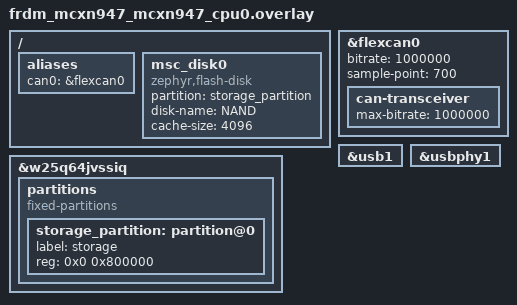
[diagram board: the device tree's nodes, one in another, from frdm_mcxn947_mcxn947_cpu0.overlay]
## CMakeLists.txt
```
# SPDX-License-Identifier: Apache-2.0

cmake_minimum_required(VERSION 3.20.0)

find_package(Zephyr REQUIRED HINTS $ENV{ZEPHYR_BASE})
project(LASER_DAQ)

target_sources(app PRIVATE src/main.c src/Proto/can_proto.c src/Proto/can_sniffer.c src/Proto/can_collect.c)
```

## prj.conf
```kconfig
# ================================================================
# LASER DAQ — Zephyr Kconfig
# ================================================================

# ---- CAN 总线 — 传统 CAN, 1 Mbps ----
CONFIG_CAN=y
# 启用 CAN 子系统
CONFIG_CAN_MCUX_FLEXCAN=y
# NXP MCUX FlexCAN 驱动 (flexcan0/flexcan1)
CONFIG_CAN_LOG_LEVEL_ERR=y
# CAN 驱动日志仅 ERR 级别 (屏蔽空总线 UnHandled status WRN 刷屏)

# ---- 日志 ----
CONFIG_LOG=y
# 启用 Zephyr 日志子系统 (LOG_INF/LOG_ERR 等)

# ---- 存储: Flash + FatFS (W25Q64JV NOR Flash, 8 MB) ----
CONFIG_FLASH=y
# 启用 Flash 驱动子系统
CONFIG_FLASH_MAP=y
# 启用 Flash 分区映射 (overlay 中 partition 需要)
CONFIG_FLASH_PAGE_LAYOUT=y
# 启用页布局查询
CONFIG_FILE_SYSTEM=y
# 启用 VFS 虚拟文件系统层 (统一 fs_open/fs_write 接口)
CONFIG_FAT_FILESYSTEM_ELM=y
# 启用 FatFS (FAT32, PC 兼容)
CONFIG_FS_FATFS_MOUNT_MKFS=y
# 挂载失败时自动格式化
CONFIG_FS_FATFS_LFN=y
# 支持长文件名
CONFIG_FS_FATFS_REENTRANT=y
# FatFS 可重入 (多线程安全, 嗅探定时器 + 主线程并发访问)

# ---- USB 设备栈 (HS USB, Mass Storage) ----
CONFIG_USB_DEVICE_STACK_NEXT=y
# 启用 USB Device Stack Next (新一代 USBD 栈)
CONFIG_USBD_MSC_CLASS=y
# 启用 USB Mass Storage Class 驱动
CONFIG_USBD_MSC_LUNS_PER_INSTANCE=1
# 注册 1 个逻辑单元 (对应 W25Q64JV)
CONFIG_DISK_DRIVER_FLASH=y
# 启用 Flash 磁盘驱动 (将 Flash 分区作为块设备)

# ---- 栈大小 ----
CONFIG_MAIN_STACK_SIZE=4096
# main 线程栈 4KB (FatFS 目录遍历结构较大, 默认 2KB 不够)

# ---- 浮点支持 ----
CONFIG_FPU=y
# 启用硬件 FPU (Cortex-M33 支持单精度)
CONFIG_PICOLIBC_IO_FLOAT=y
# 启用 picolibc 浮点 I/O (%f 格式化)
CONFIG_CBPRINTF_FP_SUPPORT=y
# 启用 cbprintf 浮点格式化支持
CONFIG_REQUIRES_FLOAT_PRINTF=y
# 声明需要浮点打印

# ---- 系统重启 ----
CONFIG_REBOOT=y
# 启用 sys_reboot 系统重启 (EraseFlash 后自动重启)

# ---- 内核堆内存池 ----
CONFIG_HEAP_MEM_POOL_SIZE=4096
# 启用 k_malloc/k_free 动态内存分配 (默认 0=禁用, 这里设为 4KB)
```

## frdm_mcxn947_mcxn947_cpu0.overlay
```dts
/*
 * LASER DAQ — FRDM-MCXN947 设备树覆盖
 *
 * 对端设备: GD32F407 (CAN2, PB5/PB6), 1Mbps, 70% 采样点, 标准帧
 * 本端硬件: FRDM-MCXN947 flexcan0, PIO1_10 (TXD) / PIO1_11 (RXD)
 * 收发器:   TJA1057 (3.3V, 最大 1 Mbps)
 * 存储:     W25Q64JV (8 MB SPI NOR, 挂载在 FlexSPI)
 */

/* ---- 别名: 芯片无关命名, 代码中通过 DT_ALIAS 引用 ---- */

/{
    aliases {
        can0 = &flexcan0;     /* can0 → flexcan0, 代码用 DT_ALIAS(can0) 获取设备 */
    };
};

/* ---- CAN 控制器: flexcan0, 传统 CAN, 1 Mbps, 70% 采样点 ---- */

&flexcan0 {
    status = "okay";          /* 使能 CAN 控制器 (默认 disabled) */
    bitrate = <1000000>;      /* 波特率 1 Mbps */
    sample-point = <700>;     /* 采样点 70.0% (对齐 GD32 端 BS1=13TQ BS2=6TQ) */

    can-transceiver {
        /* TJA1057 — 传统 CAN 收发器, 最大 1 Mbps */
        max-bitrate = <1000000>;
    };
};

/* ---- 外部 Flash: W25Q64JV (8 MB SPI NOR, FlexSPI 接口) ---- */

&w25q64jvssiq {
    status = "okay";          /* 使能 NOR Flash (默认 disabled) */

    partitions {
        compatible = "fixed-partitions";  /* 固定分区表, Zephyr flash_map 识别 */
        #address-cells = <1>;             /* 分区起始地址: 1 个 32-bit 单元 */
        #size-cells = <1>;                /* 分区大小:     1 个 32-bit 单元 */

        storage_partition: partition@0 {  /* 标签 = storage_partition, 代码中引用 */
            label = "storage";            /* 分区名 (调试/识别用) */
            reg = <0x0 0x800000>;         /* 起始 0x0, 大小 0x800000 = 8 MB, 整片用作 FatFS */
        };
    };
};

/* ---- HS USB: USB1 (EHCI, 480 Mbps), 用作 Mass Storage Device ---- */

&usb1 {
    status = "okay";          /* 使能 USB1 控制器 */
};

&usbphy1 {
    status = "okay";          /* 使能 USB1 物理层 (PHY) */
};

/* MSC 磁盘: 将 Flash 分区暴露为 USB 大容量存储设备 */

/ {
    msc_disk0 {
        compatible = "zephyr,flash-disk";    /* Zephyr Flash 磁盘驱动 */
        partition = <&storage_partition>;     /* 绑定到 storage_partition 分区 */
        disk-name = "NAND";                  /* 磁盘名 (Kconfig 中 MASS_STORAGE_DISK_NAME 一致) */
        cache-size = <4096>;                 /* 读写缓存大小 (4 KB) */
    };
};
```

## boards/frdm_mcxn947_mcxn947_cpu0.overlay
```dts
/*
 * LASER DAQ — CAN 设备树覆盖
 *
 * 对端设备: GD32F407 (CAN2, PB5/PB6), 1Mbps, 70% 采样点, 标准帧
 * 本端硬件: FRDM-MCXN947 flexcan0, PIO1_10 (TXD) / PIO1_11 (RXD)
 * 收发器:   TJA1057 (3.3V, 最大 1 Mbps)
 */

&flexcan0 {
	status = "okay";
	bitrate = <1000000>;
	sample-point = <700>;
	sjw = <1>;

	can-transceiver {
		/* TJA1057 — 传统 CAN, 最大 1 Mbps */
		max-bitrate = <1000000>;
	};
};
```

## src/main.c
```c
/*
 * LASER_DAQ - MCXN947 Laser Sensor Data Acquisition
 *
 * 目标: 通过 CAN 总线接入激光传感器，捕获测量数据
 *       在 LCD 屏幕上实时显示采集状态
 *       通过网络（Ethernet/ESP32）将数据上传至服务器
 *       数据用于后续机器学习模型训练
 *
 * FRDM-MCXN947 (Cortex-M33, 150MHz)
 *
 * CAN 协议: 对齐 GD32 GSK5G_MCU 的 can_cmd.h
 *   - MCXN947 node_id = 33 (主控端)
 *   - GD32F407  node_id = 2  (被控端)
 *   - CAN ID = (func_code << 7) | (node_id & 0x7F)
 */

#include <stdint.h>
#include <stdio.h>
#include <zephyr/kernel.h>             /* k_msleep, k_msgq 等内核 API */
#include <zephyr/device.h>             /* device_is_ready, DEVICE_DT_GET */
#include <zephyr/devicetree.h>         /* DT_NODELABEL 等设备树宏 */
#include <zephyr/drivers/can.h>        /* CAN 驱动 API */
#include <zephyr/drivers/uart.h>       /* UART 驱动 API (中断接收) */
#include <zephyr/logging/log.h>        /* 日志模块 */
#include <zephyr/fs/fs.h>			   /* 文件系统 API */

#include <zephyr/storage/flash_map.h>  /* flash_map API, 分区管理 */
#include <ff.h>                        /* FatFS API (f_mount/f_open/f_write 等) */
#include <zephyr/usb/usbd.h>           /* 新一代 USB 设备栈 */
#include <zephyr/usb/class/usbd_msc.h> /* USB Mass Storage Class */
#include <zephyr/usb/bos.h>            /* USB BOS 描述符 */
#include <zephyr/usb/usbd_msg.h>       /* USB 消息类型 (CONFIGURATION 等) */
#include <zephyr/sys/reboot.h>          /* sys_reboot 系统重启 */

#include "Proto/can_proto.h"            /* CAN 协议层 */
#include "Proto/can_sniffer.h"           /* CAN 嗅探模块 */
#include "Proto/can_collect.h"           /* CAN 数据采集模块 */
#include "zephyr/arch/arch_interface.h"
#include "zephyr/sys/printk.h"

LOG_MODULE_REGISTER(laser_daq, LOG_LEVEL_INF); /* 注册日志模块 "laser_daq" */

/* ---- 设备树设备引用 ---- */

/* 通过设备树别名 can0 获取 CAN 设备指针 */
#define CAN_DEV DEVICE_DT_GET(DT_ALIAS(can0))

/* ---- USB Mass Storage 逻辑单元注册 ---- */

USBD_DEFINE_MSC_LUN(nand, "NAND", "Zephyr", "LASER DAQ", "1.00"); /* 注册 MSC LUN */

/* ---- USB 设备上下文 ---- */

USBD_DEVICE_DEFINE(laser_usbd,                        /* 设备上下文名 */
		   DEVICE_DT_GET(DT_NODELABEL(zephyr_udc0)), /* UDC 设备 */
		   0x2FE3, 0x0008);                     /* VID=Zephyr, PID=0008 */

/* USB 字符串描述符 */
USBD_DESC_LANG_DEFINE(laser_lang);                    /* 语言描述符 */
USBD_DESC_MANUFACTURER_DEFINE(laser_mfr, "LASER DAQ");  /* 制造商 */
USBD_DESC_PRODUCT_DEFINE(laser_product, "LASER DAQ");    /* 产品名 */

/* USB 配置描述符 */
USBD_DESC_CONFIG_DEFINE(laser_fs_cfg, "FS MSC");      /* 全速配置描述符 */
USBD_DESC_CONFIG_DEFINE(laser_hs_cfg, "HS MSC");      /* 高速配置描述符 */

/* USB 配置 (全速 + 高速) */
USBD_CONFIGURATION_DEFINE(laser_fs_config, 0, 100, &laser_fs_cfg);  /* 全速 */
USBD_CONFIGURATION_DEFINE(laser_hs_config, 0, 100, &laser_hs_cfg);  /* 高速 */

/* ---- 全局状态 ---- */

static FATFS fat_fs;                     /* FatFS 文件系统对象 (持久化) */
static volatile bool g_storage_locked;    /* USB 连接时置 true, 暂停文件写入 */

/* ---- 串口指令接收 ---- */

#define UART_DEV DEVICE_DT_GET(DT_CHOSEN(zephyr_console)) /* 控制台 UART */
#define UART_CMD_BUF_SIZE 32                               /* 指令缓冲 */

static char s_cmd_buf[UART_CMD_BUF_SIZE];                  /* 行缓冲 */
static int s_cmd_pos;                                      /* 写指针 */

// 网络协议数据结构体
typedef struct {
	uint32_t timestamp;  // 时间戳
	uint16_t node_id;    // 节点 ID
	uint16_t data_length; // 数据长度
	uint8_t data[256];   // 数据内容
} net_data_t;

// 链表结构体定义
typedef struct list {
	struct list *prev;
	net_data_t data;
	struct list *next;
} list_t; 

static list_t head; // 哨兵节点
// 链表内存池定义
K_MEM_SLAB_DEFINE(my_mem_slab, sizeof(list_t), 10, 4);  /* 定义内存池: 10 个节点, 每个节点大小为 sizeof(list_t) */

/* ---- 擦除 Flash 格式化 ---- */

static void erase_flash_and_format(void)
{
	printk("\n=== EraseFlash START ===\n");

	/* 1. 卸载 FatFS */
	FRESULT fres = f_mount(NULL, "NAND:", 0);
	printk("Unmount: %d\n", fres);

	/* 2. 格式化 */
	uint8_t work[FF_MAX_SS];                  /* mkfs 工作缓冲 */
	MKFS_PARM mkfs_opt = {
		.fmt = FM_ANY | FM_SFD,           /* 自动选择 FAT 类型 */
		.n_fat = 1,                       /* 单 FAT 表 */
		.align = 0,                       /* 自动获取扇区大小 */
		.n_root = 512,                    /* 根目录条目数 */
		.au_size = 0                      /* 自动计算簇大小 */
	};
	fres = f_mkfs("NAND:", &mkfs_opt, work, sizeof(work));
	printk("Format: %d (%s)\n", fres, (fres == FR_OK) ? "OK" : "FAIL");

	/* 3. 重启系统 — 格式化后让启动流程自动挂载并重建目录 */
	printk("Rebooting in 1s...\n\n");
	k_msleep(1000);                               /* 等待日志输出完成 */
	sys_reboot(SYS_REBOOT_COLD);                  /* 冷重启 */
}

/* ---- UART RX 中断回调 ---- */

static void uart_rx_cb(const struct device *dev, void *user_data)
{
	(void)user_data;
	uint8_t c;

	/* 从 FIFO 取出所有已接收的字节 */
	while (uart_fifo_read(dev, &c, 1) == 1) {
		if (c == '\r' || c == '\n') {
			/* 换行 → 指令完成 */
			if (s_cmd_pos > 0) {
				s_cmd_buf[s_cmd_pos] = '\0';
				printk("\n[CMD] %s\n", s_cmd_buf);

				/* 匹配指令 */
				if (strcmp(s_cmd_buf, "EraseFlash") == 0) {
					erase_flash_and_format();
				} else if (strcmp(s_cmd_buf, "CollectStart") == 0) {
					can_collect_start();          /* 启动采集 */
				} else if (strcmp(s_cmd_buf, "CollectStop") == 0) {
					can_collect_stop();           /* 停止采集 */
				} else if (strcmp(s_cmd_buf, "Collect?") == 0) {
					printk("Collect: %s (seq=%u)\n",
					       can_collect_is_active() ? "ACTIVE" : "STOPPED",
					       can_collect_get_period()); /* 查状态 */
				} else if (strncmp(s_cmd_buf, "Period=", 7) == 0) {
					uint32_t period;
					if (sscanf(s_cmd_buf + 7, "%u", &period) == 1) {
						can_collect_set_period(period); /* 写入配置, 需重启生效 */
					} else {
						printk("Usage: Period=500\n");
					}
				} else if (strcmp(s_cmd_buf, "Period?") == 0) {
					printk("Period: %u ms (default 500)\n",
					       can_collect_get_period());
				} else if (strcmp(s_cmd_buf, "Help?") == 0) {
					printk(
						"\n=== LASER DAQ Commands ===\n"
						"CollectStart  - Start data collection\n"
						"CollectStop   - Stop data collection\n"
						"Collect?      - Query collection status\n"
						"Period=N      - Set report period (50-60000ms, reboot)\n"
						"Period?       - Query report period\n"
						"EraseFlash    - Format NOR flash\n"
						"Help?         - Show this help\n"
					);
				} else {
					printk("Unknown: %s\n", s_cmd_buf);
				}
				s_cmd_pos = 0;
			}
		} else if (c == '\b' || c == 0x7F) {
			/* 退格 */
			if (s_cmd_pos > 0) s_cmd_pos--;
		} else if (c >= ' ' && c <= '~') {
			/* 可打印字符 */
			if (s_cmd_pos < UART_CMD_BUF_SIZE - 1) {
				s_cmd_buf[s_cmd_pos++] = c;
				printk("%c", c);          /* 回显 */
			}
		}
	}
}

/* ---- USB 消息回调: 检测主机连接/断开 ---- */

static void usb_status_cb(struct usbd_context *const ctx,
			  const struct usbd_msg *const msg)
{
	if (msg->type == USBD_MSG_CONFIGURATION) {
		/* status != 0 → 主机已配置设备, 文件系统被 PC 独占 */
		g_storage_locked = (msg->status != 0);
		if (g_storage_locked) {
			LOG_WRN("USB configured, storage writes suspended");
		} else {
			LOG_INF("USB deconfigured, storage writes resumed");
		}
	} else if (msg->type == USBD_MSG_VBUS_REMOVED) {
		/* VBUS 移除 → 物理断开, 恢复文件写入 */
		g_storage_locked = false;
		LOG_INF("USB disconnected, storage writes resumed");
	}
}

/* ---- 子系统初始化 ---- */

static int init_can_collector(void);    /* CAN 数据采集子系统 */
static int init_storage(void);          /* FatFS 存储子系统 */
static int init_usb_msc(void);          /* USB MSC 初始化 */
static int init_lcd_display(void);      /* LCD 显示子系统 */
static int init_network_upload(void);   /* 网络上传子系统 */
static int init_uart_cmd(void);         /* 串口指令接收 */

/* ---- 线程入口 ---- */

void can_rx_thread(void *, void *, void *);  /* CAN 接收处理线程 */

/* 线程栈定义 */
K_THREAD_DEFINE(can_rx_tid, 2048,       /* 线程 ID + 栈大小 2048 字节 */
		can_rx_thread, NULL, NULL, NULL, /* 入口函数 + 参数（无） */
		7, 0, 0);                       /* 优先级 7, 无延迟启动 */

/* ================================================================
 * USB Mass Storage 初始化
 * ================================================================ */

static int init_usb_msc(void)
{
	int err;                                      /* 返回值 */

	/* 注册 USB 字符串描述符 */
	err = usbd_add_descriptor(&laser_usbd, &laser_lang); /* 语言 */
	if (err) { return err; }
	err = usbd_add_descriptor(&laser_usbd, &laser_mfr);  /* 制造商 */
	if (err) { return err; }
	err = usbd_add_descriptor(&laser_usbd, &laser_product); /* 产品名 */
	if (err) { return err; }

	/* 注册全速配置 + 高速配置 + 自动注册 MSC 类 */
	err = usbd_add_configuration(&laser_usbd, USBD_SPEED_FS, &laser_fs_config);
	if (err) { return err; }
	err = usbd_register_all_classes(&laser_usbd, USBD_SPEED_FS, 1, NULL);
	if (err) { return err; }

	if (usbd_caps_speed(&laser_usbd) == USBD_SPEED_HS) {
		err = usbd_add_configuration(&laser_usbd, USBD_SPEED_HS,
					     &laser_hs_config); /* 高速配置 */
		if (err) { return err; }
		err = usbd_register_all_classes(&laser_usbd, USBD_SPEED_HS,
						1, NULL);   /* 注册 MSC 类 */
		if (err) { return err; }
	}

	/* 初始化并启用 USB 设备 */
	err = usbd_init(&laser_usbd);                 /* 初始化 USBD 栈 */
	if (err) { return err; }
	usbd_msg_register_cb(&laser_usbd, usb_status_cb); /* 注册 USB 状态回调 */
	err = usbd_enable(&laser_usbd);               /* 启用 USB, 开始枚举 */
	if (err) { return err; }

	return 0;                                     /* 成功 */
}

/* ================================================================
 * main — 系统入口
 * ================================================================ */

int main(void)
{
	printk("\n========================================\n");  /* 启动横幅 */
	printk("  MCXN947 Laser Data Collector\n");
	printk("========================================\n\n");

	LOG_INF("System boot complete, initializing subsystems...");  /* 日志: 启动完成 */

	/* 1. CAN 数据采集子系统 — flexcan0 @ 1Mbps, 70% 采样点 */
	if (init_can_collector() < 0) {
		LOG_ERR("CAN collector init failed");   /* 初始化失败日志 */
	}

	/* 2. FatFS 存储子系统 — W25Q64JV NOR Flash 8 MB */
	if (init_storage() < 0) {
		LOG_ERR("Storage init failed");         /* 存储初始化失败 */
	}

	/* 3. 串口指令 — 接收 EraseFlash 等控制台指令 */
	if (init_uart_cmd() < 0) {
		LOG_ERR("UART CMD init failed");        /* 串口初始化失败 */
	}

	/* 4. USB Mass Storage — HS USB, 暴露 /NAND: 为 U 盘 */
	if (init_usb_msc() < 0) {
		LOG_ERR("USB MSC init failed");         /* USB 初始化失败 */
	}

	/* 5. LCD 显示子系统 */
	if (init_lcd_display() < 0) {
		LOG_ERR("LCD display init failed");
	}

	/* 6. CAN 嗅探 — 全量捕获总线帧, 按 node_id 存入 CSV */
	if (can_sniffer_init() < 0) {
		LOG_ERR("CAN sniffer init failed");       /* 嗅探初始化失败 */
	}

	/* 7. CAN 采集 — 主动轮询各 K64 测量值, 窄表 CSV */
	if (can_collect_init(CAN_DEV) < 0) {
		LOG_ERR("CAN collect init failed");       /* 采集初始化失败 */
	}

	/* 8. 网络上传子系统 */
	if (init_network_upload() < 0) {
		LOG_ERR("Network upload init failed");
	}

	LOG_INF("All subsystems initialized, entering main loop");  /* 就绪 */

	while (1) {
		/* 主循环: 轮询各 K64 采集数据 + 批量刷盘 */
		can_collect_poll(CAN_DEV);                /* 发送查询指令 */
		if (!g_storage_locked) {
			can_sniffer_flush();                  /* 嗅探数据写 CSV */
			can_collect_flush();                  /* 采集数据写 CSV */
		}
		k_msleep(COLLECT_POLL_PERIOD_MS);         /* 轮询间隔 */
	}

	return 0;
}

/* ================================================================
 * CAN 数据采集子系统
 * ================================================================ */

static int init_can_collector(void)
{
	LOG_INF("CAN collector: initializing flexcan0...");  /* 开始初始化 */

	/* 步骤1: 检查设备是否就绪（设备树已配置 + 驱动已加载） */
	if (!device_is_ready(CAN_DEV)) {
		LOG_ERR("CAN device not ready");      /* 设备不可用 */
		return -1;
	}
	LOG_INF("CAN device found: %s", CAN_DEV->name);  /* 打印设备名 */

	/* 步骤2: 设置为环回模式, 进行自检 */
	int ret = can_set_mode(CAN_DEV, CAN_MODE_LOOPBACK); /* 环回模式 */
	if (ret != 0) {
		LOG_ERR("CAN set loopback mode failed: %d", ret); /* 模式设置失败 */
		return -1;
	}

	/* 步骤3: 初始化协议层 (配置 RX 滤波器, 设置 node_id=33) */
	ret = can_proto_init(CAN_DEV);
	if (ret < 0) {
		LOG_ERR("CAN proto init failed: %d", ret); /* 协议初始化失败 */
		return -1;
	}

	/* 步骤4: 启动 CAN 控制器 */
	ret = can_start(CAN_DEV);
	if (ret != 0) {
		LOG_ERR("CAN start failed: %d", ret);  /* 启动失败 */
		return -1;
	}

	/* 步骤5: 环回自检 — TX→RX 内部回环, 验证通信通路 */
	can_proto_loopback_test(CAN_DEV);                /* 发送 3 帧测试数据 */

	/* 步骤6: 切换到正常模式 */
	can_stop(CAN_DEV);                               /* 先停止 */
	ret = can_set_mode(CAN_DEV, CAN_MODE_NORMAL);    /* 正常模式 */
	if (ret != 0) {
		LOG_ERR("CAN set normal mode failed: %d", ret); /* 切换失败 */
		return -1;
	}
	ret = can_start(CAN_DEV);                        /* 重新启动 */
	if (ret != 0) {
		LOG_ERR("CAN restart failed: %d", ret);    /* 重启失败 */
		return -1;
	}

	LOG_INF("CAN collector: flexcan0 started, 1Mbps, node_id=%d, waiting for frames",
		g_can_node_id);                           /* 打印节点 ID */
	return 0;  /* 成功 */
}

/* ================================================================
 * CAN 接收线程 — 协议派发
 * ================================================================ */

void can_rx_thread(void *arg1, void *arg2, void *arg3)
{
	(void)arg1; (void)arg2; (void)arg3;        /* 未使用参数 */

	struct can_frame frame;                      /* CAN 帧缓冲区 */
	int drained;                                 /* 本次排空帧数 */

	while (1) {
		drained = 0;
		/* 批量排空消息队列: 避免单帧处理期间新帧堆积溢出 */
		while (k_msgq_get(&can_rx_msgq, &frame, K_NO_WAIT) == 0) {
			can_sniffer_feed(&frame);             /* 原始嗅探 */
			can_collect_feed(&frame);             /* 采集解析 */
			drained++;
		}
		/* 队列空则阻塞等待下一帧 */
		if (drained == 0) {
			k_msgq_get(&can_rx_msgq, &frame, K_FOREVER);
			can_sniffer_feed(&frame);             /* 原始嗅探 */
			can_collect_feed(&frame);             /* 采集解析 */
		}
	}
}

/* ================================================================
 * FatFS + USB MSC 存储子系统 — W25Q64JV NOR Flash 8 MB
 * ================================================================ */

/* 递归遍历目录, 打印文件/子目录 */
static void print_dir(const char *path, int depth)
{
	struct fs_dir_t dir;
	fs_dir_t_init(&dir);                          /* 初始化目录对象 */
	int ret = fs_opendir(&dir, path);             /* 打开目录 */
	if (ret < 0) {
		LOG_WRN("Cannot open %s: %d", path, ret); /* 打开失败 */
		return;
	}

	while (1) {
		struct fs_dirent entry = { 0 };           /* 目录项 */
		ret = fs_readdir(&dir, &entry);           /* 读取一条 */
		if (ret < 0 || entry.name[0] == '\0') {
			break;                                /* 读完或出错 */
		}

		/* 跳过 . 和 .. */
		if (entry.name[0] == '.' && (entry.name[1] == '\0' ||
		    (entry.name[1] == '.' && entry.name[2] == '\0'))) {
			continue;
		}

		/* 缩进打印 */
		for (int i = 0; i < depth; i++) {
			printk("  ");                         /* 每层缩进2空格 */
		}
		printk("%c %8zu %s\n",
		       (entry.type == FS_DIR_ENTRY_DIR) ? 'D' : 'F', /* 类型 */
		       entry.size,                         /* 大小 */
		       entry.name);                        /* 名称 */

		/* 递归进入子目录 */
		if (entry.type == FS_DIR_ENTRY_DIR) {
			char sub_path[280];                   /* 子目录路径 */
			snprintf(sub_path, sizeof(sub_path), "%s/%s", path, entry.name);
			print_dir(sub_path, depth + 1);       /* 递归遍历 */
		}
	}
	fs_closedir(&dir);                            /* 关闭目录 */
}

static int init_storage(void)
{
	LOG_INF("Storage: mounting FatFS on W25Q64JV..."); /* 开始挂载 */

	int ret;                                      /* 返回值 */

	/* 配置挂载参数 */
	struct fs_mount_t mp = {
		.type = FS_FATFS,                         /* 文件系统类型: FatFS */
		.fs_data = &fat_fs,                       /* FatFS 对象 */
		.storage_dev = (void *)PARTITION_ID(storage_partition), /* Flash 分区 */
		.mnt_point = "/NAND:",                    /* 挂载点 */
	};

	ret = fs_mount(&mp);                          /* 执行挂载 */
	if (ret < 0) {
		LOG_ERR("FatFS mount failed: %d", ret);   /* 挂载失败 */
		return -1;
	}
	LOG_INF("FatFS mounted at /NAND:");           /* 挂载成功 */

	/* 打印文件系统信息 */
	struct fs_statvfs stat;
	ret = fs_statvfs("/NAND:", &stat);            /* 查询文件系统状态 */
	if (ret == 0) {
		LOG_INF("FS: block=%luB total=%lu free=%lu",
			stat.f_bsize,                         /* 块大小 */
			stat.f_blocks,                        /* 总块数 */
			stat.f_bfree);                        /* 空闲块数 */
	}

	/* 递归遍历并打印文件系统内容 */
	LOG_INF("--- /NAND: contents ---");           /* 列表头 */
	print_dir("/NAND:/", 0);                      /* 从根目录开始 (尾随斜杠) */
	LOG_INF("--- end of list ---");

	LOG_INF("Storage init done, USB MSC ready");   /* 初始化完成 */
	return 0;
}

/* ================================================================
 * 串口指令接收 — 通过控制台 UART 接收 "EraseFlash" 等指令
 * ================================================================ */

static int init_uart_cmd(void)
{
	if (!device_is_ready(UART_DEV)) {
		LOG_ERR("UART device not ready");
		return -1;
	}

	/* 注册中断回调 */
	uart_irq_callback_set(UART_DEV, uart_rx_cb);

	/* 使能 RX 中断 */
	uart_irq_rx_enable(UART_DEV);

	printk("\nSerial CMD ready. Type 'EraseFlash' to format NOR flash.\n");
	LOG_INF("UART CMD listener started");
	return 0;
}

/* ================================================================
 * LCD 显示子系统（占位）
 * ================================================================ */

static int init_lcd_display(void)
{
	LOG_INF("LCD display: initializing ST7796S via FlexIO...");
	/* TODO: 初始化 LCD，显示采集状态界面 */
	return 0;  /* 占位返回成功 */
}

/* ================================================================
 * 网络上传子系统（占位）
 * ================================================================ */

static int init_network_upload(void)
{
	LOG_INF("Network upload: initializing Ethernet/ESP32...");
	/* TODO: 初始化网络栈，连接上传服务器 */
	
	// 链表测试
	// 初始化哨兵节点
	head.prev = &head;
	head.next = &head;

	list_t *node = NULL;
	k_mem_slab_alloc(&my_mem_slab, (void **)&node, K_NO_WAIT);  /* 分配链表节点 */
	if (node == NULL) {
		LOG_ERR("Failed to allocate memory for new node");
		return -1;
	}
	node->data.timestamp = 1234567890;  /* 测试数据 */
	node->data.node_id = 33;
	node->data.data_length = 4;
	node->data.data[0] = 0xDE;
	node->data.data[1] = 0xAD;
	node->data.data[2] = 0xBE;
	node->data.data[3] = 0xEF;
	node->prev = &head;
	node->next = &head;
	head.prev = node;
	head.next = node;

	list_t *current = head.next;
	while (current != &head) {
		printf("Node: %p, Data: %lu, %d\n", (void *)current, current->data.timestamp, current->data.node_id);
		current = current->next;
	}

	
	return 0;  /* 占位返回成功 */
}
```
